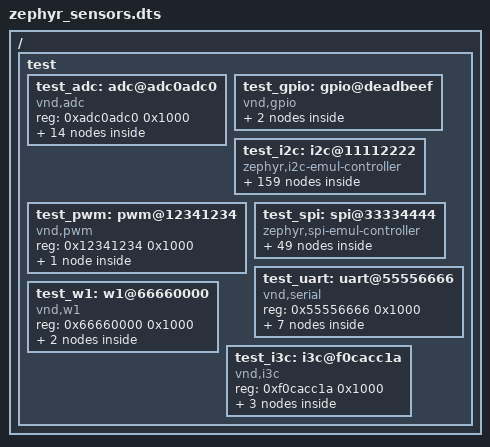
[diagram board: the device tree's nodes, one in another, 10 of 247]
/dts-v1/;

/ {
	test {
		#address-cells = < 0x1 >;
		#size-cells = < 0x1 >;
		test_adc: adc@adc0adc0 {
			compatible = "vnd,adc";
			reg = < 0xadc0adc0 0x1000 >;
			#io-channel-cells = < 0x1 >;
			#address-cells = < 0x1 >;
			#size-cells = < 0x0 >;
			status = "okay";
			phandle = < 0x1 >;
			channel@0 {
				reg = < 0x0 >;
				zephyr,gain = "ADC_GAIN_1";
				zephyr,reference = "ADC_REF_VDD_1";
				zephyr,acquisition-time = < 0x0 >;
				zephyr,input-positive = < 0x0 >;
				zephyr,resolution = < 0xc >;
			};
			channel@1 {
				reg = < 0x1 >;
				zephyr,gain = "ADC_GAIN_1_6";
				zephyr,reference = "ADC_REF_INTERNAL";
				zephyr,acquisition-time = < 0x0 >;
				zephyr,input-positive = < 0x0 >;
				zephyr,resolution = < 0xc >;
			};
			channel@2 {
				reg = < 0x2 >;
				zephyr,gain = "ADC_GAIN_1_6";
				zephyr,reference = "ADC_REF_INTERNAL";
				zephyr,acquisition-time = < 0x0 >;
				zephyr,input-positive = < 0x0 >;
				zephyr,resolution = < 0xc >;
			};
			test_adc_mcp9700a: mcp9700a {
				status = "okay";
				compatible = "microchip,mcp970x";
				family = "MCP9700/9700A";
				io-channels = < &test_adc 0x0 >;
			};
			test_voltage: voltage {
				status = "okay";
				compatible = "voltage-divider";
				io-channels = < &test_adc 0x1 >;
				io-channel-names = "VOLTAGE";
				output-ohms = < 0xb798 >;
				full-ohms = < 0x23e38 >;
				power-gpios = < &test_gpio 0x0 0x0 >;
				phandle = < 0x3 >;
			};
			test_current: current_amp {
				status = "okay";
				compatible = "current-sense-amplifier";
				io-channels = < &test_adc 0x2 >;
				io-channel-names = "CURRENT_AMP";
				sense-resistor-micro-ohms = < 0xa >;
				sense-gain-mult = < 0x1 >;
				sense-gain-div = < 0x1 >;
				phandle = < 0x4 >;
			};
			test_composite_fuel_gauge: composite_fuel_gauge {
				compatible = "zephyr,fuel-gauge-composite";
				status = "okay";
				battery-voltage = < &test_voltage >;
				battery-current = < &test_current >;
				device-chemistry = "lithium-ion-polymer";
				ocv-capacity-table-0 = < 0x262d70 0x300110 0x3373e0 0x34a0a8 0x35e4e0 0x36f650 0x382700 0x396f20 0x3a9fd0 0x3c0f00 0x3d8600 >;
				charge-full-design-microamp-hours = < 0xf4240 >;
			};
			test_adc_emul: adc-emul {
				compatible = "zephyr,adc-emul";
				nchannels = < 0x2 >;
				ref-internal-mv = < 0xce4 >;
				ref-external1-mv = < 0x1388 >;
				#io-channel-cells = < 0x1 >;
				status = "okay";
			};
			test_adc_ntc_thermistor_generic: ntc-thermistor-generic {
				compatible = "ntc-thermistor-generic";
				io-channels = < &test_adc 0x0 >;
				pullup-uv = < 0x325aa0 >;
				pullup-ohm = < 0x0 >;
				pulldown-ohm = < 0x2710 >;
				connected-positive;
				zephyr,compensation-table = < 0x0 0x0 >, < 0x1 0x1 >;
			};
			test_adc_epcos_b57861s0103a039: epcos-b57861s0103a039 {
				compatible = "epcos,b57861s0103a039";
				io-channels = < &test_adc 0x0 >;
				pullup-uv = < 0x325aa0 >;
				pullup-ohm = < 0x0 >;
				pulldown-ohm = < 0x2710 >;
				connected-positive;
			};
			test_murata_ncp15wb473: murata-ncp15wb473 {
				compatible = "murata,ncp15wb473";
				io-channels = < &test_adc 0x0 >;
				pullup-uv = < 0x325aa0 >;
				pullup-ohm = < 0x0 >;
				pulldown-ohm = < 0x2710 >;
				connected-positive;
			};
			test_tdk_ntcg163jf103ft1: tdk-ntcg163jf103ft1 {
				compatible = "tdk,ntcg163jf103ft1";
				io-channels = < &test_adc 0x0 >;
				pullup-uv = < 0x325aa0 >;
				pullup-ohm = < 0x0 >;
				pulldown-ohm = < 0x2710 >;
				connected-positive;
			};
			test_lm35: lm35 {
				compatible = "lm35";
				io-channels = < &test_adc 0x0 >;
				status = "okay";
			};
			test_murata_ncp15xh103: murata-ncp15xh103 {
				compatible = "murata,ncp15xh103";
				io-channels = < &test_adc 0x0 >;
				pullup-uv = < 0x325aa0 >;
				pullup-ohm = < 0x0 >;
				pulldown-ohm = < 0x2710 >;
				connected-positive;
			};
		};
		test_gpio: gpio@deadbeef {
			compatible = "vnd,gpio";
			gpio-controller;
			reg = < 0xdeadbeef 0x1000 >;
			#gpio-cells = < 0x2 >;
			status = "okay";
			phandle = < 0x2 >;
			test_gpio_sm351lt: sm351lt0 {
				compatible = "honeywell,sm351lt";
				gpios = < &test_gpio 0x0 0x0 >;
			};
			test_gpio_dht22: dht22 {
				compatible = "aosong,dht";
				status = "okay";
				dio-gpios = < &test_gpio 0x0 0x0 >;
			};
		};
		test_i2c: i2c@11112222 {
			#address-cells = < 0x1 >;
			#size-cells = < 0x0 >;
			compatible = "zephyr,i2c-emul-controller";
			reg = < 0x11112222 0x1000 >;
			status = "okay";
			clock-frequency = < 0x186a0 >;
			test_i2c_adt7420: adt7420@0 {
				compatible = "adi,adt7420";
				reg = < 0x0 >;
				int-gpios = < &test_gpio 0x0 0x0 >;
			};
			test_i2c_adxl345: adxl345@1 {
				compatible = "adi,adxl345";
				reg = < 0x1 >;
			};
			test_i2c_adxl372: adxl372@2 {
				compatible = "adi,adxl372";
				reg = < 0x2 >;
				int1-gpios = < &test_gpio 0x0 0x0 >;
			};
			test_i2c_ccs811: ccs811@3 {
				compatible = "ams,ccs811";
				reg = < 0x3 >;
				wake-gpios = < &test_gpio 0x0 0x0 >;
				reset-gpios = < &test_gpio 0x0 0x0 >;
				irq-gpios = < &test_gpio 0x0 0x0 >;
			};
			test_i2c_ens210: ens210@4 {
				compatible = "ams,ens210";
				reg = < 0x4 >;
			};
			test_i2c_iaqcore: iaqcore@5 {
				compatible = "ams,iaqcore";
				reg = < 0x5 >;
			};
			test_i2c_bme280: bme280@6 {
				compatible = "bosch,bme280";
				reg = < 0x6 >;
			};
			test_i2c_apds9960: apds9960@7 {
				compatible = "avago,apds9960";
				reg = < 0x7 >;
				int-gpios = < &test_gpio 0x0 0x0 >;
			};
			test_i2c_bma280: bma280@8 {
				compatible = "bosch,bma280";
				reg = < 0x8 >;
				int1-gpios = < &test_gpio 0x0 0x0 >;
			};
			test_i2c_bmc150_magn: bmc150_magn@9 {
				compatible = "bosch,bmc150_magn";
				reg = < 0x9 >;
				drdy-gpios = < &test_gpio 0x0 0x0 >;
			};
			test_i2c_ak8975: ak8975@a {
				compatible = "asahi-kasei,ak8975";
				reg = < 0xa >;
			};
			test_i2c_bme680: bme680@b {
				compatible = "bosch,bme680";
				reg = < 0xb >;
			};
			test_i2c_bmg160: bmg160@c {
				compatible = "bosch,bmg160";
				reg = < 0xc >;
				int-gpios = < &test_gpio 0x0 0x0 >;
			};
			test_i2c_bmm150: bmm150@d {
				compatible = "bosch,bmm150";
				reg = < 0xd >;
				drdy-gpios = < &test_gpio 0x0 0x0 >;
			};
			test_i2c_hmc5883l: hmc5883l@e {
				compatible = "honeywell,hmc5883l";
				reg = < 0xe >;
				int-gpios = < &test_gpio 0x0 0x0 >;
			};
			test_i2c_hp206c: hp206c@f {
				compatible = "hoperf,hp206c";
				reg = < 0xf >;
			};
			test_i2c_th02: th02@10 {
				compatible = "hoperf,th02";
				reg = < 0x10 >;
			};
			test_i2c_mpu6050: mpu6050@11 {
				compatible = "invensense,mpu6050";
				reg = < 0x11 >;
				int-gpios = < &test_gpio 0x0 0x0 >;
			};
			test_i2c_mpu9250: mpu9250@12 {
				compatible = "invensense,mpu9250";
				reg = < 0x12 >;
				irq-gpios = < &test_gpio 0x0 0x0 >;
				gyro-sr-div = < 0xa >;
				gyro-dlpf = < 0x5 >;
				gyro-fs = < 0xfa >;
				accel-fs = < 0x2 >;
				accel-dlpf = "5.05";
			};
			test_i2c_ina219: ina219@13 {
				compatible = "ti,ina219";
				reg = < 0x13 >;
				brng = < 0x0 >;
				pg = < 0x0 >;
				sadc = < 0xd >;
				badc = < 0xd >;
				shunt-milliohm = < 0x64 >;
				lsb-microamp = < 0xa >;
			};
			test_i2c_isl29035: isl29035@14 {
				compatible = "isil,isl29035";
				reg = < 0x14 >;
				int-gpios = < &test_gpio 0x0 0x0 >;
			};
			test_i2c_max30101: max30101@15 {
				compatible = "maxim,max30101";
				reg = < 0x15 >;
			};
			test_i2c_max44009: max44009@16 {
				compatible = "maxim,max44009";
				reg = < 0x16 >;
				int-gpios = < &test_gpio 0x0 0x0 >;
			};
			test_i2c_ms5607: ms5607@17 {
				compatible = "meas,ms5607";
				reg = < 0x17 >;
			};
			test_i2c_ms5837: ms5837@18 {
				compatible = "meas,ms5837";
				reg = < 0x18 >;
			};
			test_i2c_jc42: jc42@19 {
				compatible = "jedec,jc-42.4-temp";
				reg = < 0x19 >;
				int-gpios = < &test_gpio 0x0 0x0 >;
			};
			test_i2c_fxas21002: fxas21002@1a {
				compatible = "nxp,fxas21002";
				reg = < 0x1a >;
				int1-gpios = < &test_gpio 0x0 0x0 >;
				int2-gpios = < &test_gpio 0x0 0x0 >;
			};
			test_i2c_fxos8700: fxos8700@1b {
				compatible = "nxp,fxos8700";
				reg = < 0x1b >;
				reset-gpios = < &test_gpio 0x0 0x0 >;
				int1-gpios = < &test_gpio 0x0 0x0 >;
				int2-gpios = < &test_gpio 0x0 0x0 >;
			};
			test_i2c_amg88xx: amg88xx@1c {
				compatible = "panasonic,amg88xx";
				reg = < 0x1c >;
				int-gpios = < &test_gpio 0x0 0x0 >;
			};
			test_i2c_sx9500: sx9500@1d {
				compatible = "semtech,sx9500";
				reg = < 0x1d >;
				int-gpios = < &test_gpio 0x0 0x0 >;
			};
			test_i2c_sgp40: sgp40@1e {
				compatible = "sensirion,sgp40";
				reg = < 0x1e >;
				enable-selftest;
			};
			test_i2c_sht3xd: sht3xd@1f {
				compatible = "sensirion,sht3xd";
				reg = < 0x1f >;
				alert-gpios = < &test_gpio 0x0 0x0 >;
			};
			test_i2c_sht4xd: sht4x@20 {
				compatible = "sensirion,sht4x";
				reg = < 0x20 >;
				repeatability = < 0x2 >;
			};
			test_i2c_shtc3: shtc3@21 {
				compatible = "sensirion,shtc3", "sensirion,shtcx";
				reg = < 0x21 >;
				measure-mode = "normal";
				clock-stretching;
			};
			test_i2c_si7006: si7006@22 {
				compatible = "silabs,si7006";
				reg = < 0x22 >;
			};
			test_i2c_si7055: si7055@23 {
				compatible = "silabs,si7055";
				reg = < 0x23 >;
			};
			test_i2c_si7060: si7060@24 {
				compatible = "silabs,si7060";
				reg = < 0x24 >;
			};
			test_i2c_si7210: si7010@25 {
				compatible = "silabs,si7210";
				reg = < 0x25 >;
			};
			test_i2c_hts221: hts221@26 {
				compatible = "st,hts221";
				reg = < 0x26 >;
				drdy-gpios = < &test_gpio 0x0 0x0 >;
			};
			test_i2c_iis2dlpc: iis2dlpc@27 {
				compatible = "st,iis2dlpc";
				reg = < 0x27 >;
				drdy-gpios = < &test_gpio 0x0 0x0 >;
				tap-mode = < 0x1 >;
				power-mode = < 0x4 >;
			};
			test_i2c_iis2mdc: iis2mdc@28 {
				compatible = "st,iis2mdc";
				reg = < 0x28 >;
				drdy-gpios = < &test_gpio 0x0 0x0 >;
			};
			test_i2c_ism330dhcx: ism330dhcx@29 {
				compatible = "st,ism330dhcx";
				reg = < 0x29 >;
				drdy-gpios = < &test_gpio 0x0 0x0 >;
				accel-odr = < 0x4 >;
				gyro-odr = < 0x4 >;
				status = "disabled";
			};
			test_i2c_lis2dh: lis2dh@2a {
				compatible = "st,lis2dh";
				reg = < 0x2a >;
				irq-gpios = < &test_gpio 0x0 0x0 >;
				int1-gpio-config = < 0x4 >;
				int2-gpio-config = < 0x4 >;
				anym-mode = < 0x3 >;
			};
			test_i2c_lis2dh12: lis2dh12@2b {
				compatible = "st,lis2dh12";
				reg = < 0x2b >;
				irq-gpios = < &test_gpio 0x0 0x0 >;
				status = "disabled";
			};
			test_i2c_lis2ds12: lis2ds12@2c {
				compatible = "st,lis2ds12";
				reg = < 0x2c >;
				irq-gpios = < &test_gpio 0x0 0x0 >;
				power-mode = < 0x1 >;
				odr = < 0x2 >;
			};
			test_i2c_lis2dw12: lis2dw12@2d {
				compatible = "st,lis2dw12";
				reg = < 0x2d >;
				irq-gpios = < &test_gpio 0x0 0x0 >;
				wakeup-duration = < 0x3 >;
				ff-threshold = < 0x7 >;
				tap-mode = < 0x1 >;
				power-mode = < 0x4 >;
				bw-filt = < 0x0 >;
			};
			test_i2c_lis2mdl: lis2mdl@2e {
				compatible = "st,lis2mdl";
				reg = < 0x2e >;
				irq-gpios = < &test_gpio 0x0 0x0 >;
			};
			test_i2c_lis3dh: lis3dh@2f {
				compatible = "st,lis3dh";
				reg = < 0x2f >;
				irq-gpios = < &test_gpio 0x0 0x0 >;
				status = "disabled";
			};
			test_i2c_lis3mdl_magn: lis3mdl-magn@30 {
				compatible = "st,lis3mdl-magn";
				reg = < 0x30 >;
				irq-gpios = < &test_gpio 0x0 0x0 >;
			};
			test_i2c_lps22hb_press: lps22hb-press@31 {
				compatible = "st,lps22hb-press";
				reg = < 0x31 >;
			};
			test_i2c_lps22hh: lps22hh@32 {
				compatible = "st,lps22hh";
				reg = < 0x32 >;
				drdy-gpios = < &test_gpio 0x0 0x0 >;
				odr = < 0x7 >;
			};
			test_i2c_lps25hb_press: lps25hb-press@33 {
				compatible = "st,lps25hb-press";
				reg = < 0x33 >;
			};
			test_i2c_lsm303agr_accel: lsm303agr-accel@34 {
				compatible = "st,lsm303agr-accel";
				reg = < 0x34 >;
				irq-gpios = < &test_gpio 0x0 0x0 >;
				status = "disabled";
			};
			test_i2c_lsm303dlhc_accel: lsm303dlhc-accel@35 {
				compatible = "st,lsm303dlhc-accel";
				reg = < 0x35 >;
				irq-gpios = < &test_gpio 0x0 0x0 >;
				status = "disabled";
			};
			test_i2c_lsm303dlhc_magn: lsm303dlhc-magn@36 {
				compatible = "st,lsm303dlhc-magn";
				reg = < 0x36 >;
			};
			test_i2c_lsm6ds0: lsm6ds0@37 {
				compatible = "st,lsm6ds0";
				reg = < 0x37 >;
			};
			test_i2c_lsm6dsl: lsm6dsl@38 {
				compatible = "st,lsm6dsl";
				reg = < 0x38 >;
				irq-gpios = < &test_gpio 0x0 0x0 >;
			};
			test_i2c_lsm6dso: lsm6dso@39 {
				compatible = "st,lsm6dso";
				reg = < 0x39 >;
				irq-gpios = < &test_gpio 0x0 0x0 >;
				accel-pm = < 0x2 >;
				accel-range = < 0x3 >;
				accel-odr = < 0xb >;
				gyro-pm = < 0x1 >;
				gyro-range = < 0x6 >;
				gyro-odr = < 0xa >;
			};
			test_i2c_lsm9ds0_gyro: lsm9ds0-gyro@3a {
				compatible = "st,lsm9ds0-gyro";
				reg = < 0x3a >;
				irq-gpios = < &test_gpio 0x0 0x0 >;
			};
			test_i2c_lsm9ds0_mfd: lsm9ds0-mfd@3b {
				compatible = "st,lsm9ds0-mfd";
				reg = < 0x3b >;
				irq-gpios = < &test_gpio 0x0 0x0 >;
			};
			test_i2c_stts751: stts751@3c {
				compatible = "st,stts751";
				reg = < 0x3c >;
				drdy-gpios = < &test_gpio 0x0 0x0 >;
			};
			test_i2c_vl53l0x: vl53l0x@3d {
				compatible = "st,vl53l0x";
				reg = < 0x3d >;
				xshut-gpios = < &test_gpio 0x0 0x0 >;
			};
			test_i2c_hdc: hdc@3e {
				compatible = "ti,hdc";
				reg = < 0x3e >;
				drdy-gpios = < &test_gpio 0x0 0x0 >;
			};
			test_i2c_hdc2010: hdc2010@3f {
				compatible = "ti,hdc2010";
				reg = < 0x3f >;
			};
			test_i2c_hdc2021: hdc2021@40 {
				compatible = "ti,hdc2021";
				reg = < 0x40 >;
			};
			test_i2c_hdc2022: hdc2022@41 {
				compatible = "ti,hdc2022";
				reg = < 0x41 >;
			};
			test_i2c_hdc2080: hdc2080@42 {
				compatible = "ti,hdc2080";
				reg = < 0x42 >;
			};
			test_i2c_opt3001: opt3001@43 {
				compatible = "ti,opt3001";
				reg = < 0x43 >;
			};
			test_i2c_tmp007: tmp007@44 {
				compatible = "ti,tmp007";
				reg = < 0x44 >;
				int-gpios = < &test_gpio 0x0 0x0 >;
			};
			test_i2c_tmp108: tmp108@45 {
				compatible = "ti,tmp108";
				reg = < 0x45 >;
				alert-gpios = < &test_gpio 0x0 0x0 >;
			};
			test_i2c_tmp112: tmp112@46 {
				compatible = "ti,tmp112";
				reg = < 0x46 >;
			};
			test_i2c_tmp116: tmp116@47 {
				compatible = "ti,tmp116";
				reg = < 0x47 >;
			};
			test_i2c_bq274xx: bq27xx@48 {
				compatible = "ti,bq274xx";
				reg = < 0x48 >;
				design-voltage = < 0xe74 >;
				design-capacity = < 0x708 >;
				taper-current = < 0x2d >;
				terminate-voltage = < 0xbb8 >;
				int-gpios = < &test_gpio 0x0 0x0 >;
			};
			test_i2c_mpr: mpr@49 {
				compatible = "honeywell,mpr";
				reg = < 0x49 >;
			};
			test_i2c_dps310: dps310@4a {
				compatible = "infineon,dps310";
				reg = < 0x4a >;
			};
			test_i2c_iis2dh: iis2dh@4b {
				compatible = "st,iis2dh";
				reg = < 0x4b >;
				drdy-gpios = < &test_gpio 0x0 0x0 >;
			};
			test_i2c_iis2iclx: iis2iclx@4c {
				compatible = "st,iis2iclx";
				reg = < 0x4c >;
				drdy-gpios = < &test_gpio 0x0 0x0 >;
				int-pin = < 0x1 >;
				range = < 0x3 >;
				odr = < 0x7 >;
			};
			test_i2c_wsen_hids: wsen_hids@4d {
				compatible = "we,wsen-hids";
				reg = < 0x4d >;
				drdy-gpios = < &test_gpio 0x0 0x0 >;
				odr = "1";
			};
			test_i2c_itds: itds@4e {
				compatible = "we,wsen-itds";
				reg = < 0x4e >;
				int-gpios = < &test_gpio 0x0 0x0 >;
				odr = "800";
				op-mode = "high-perf";
			};
			test_i2c_max17055: max17055@4f {
				compatible = "maxim,max17055";
				reg = < 0x4f >;
				design-capacity = < 0x5dc >;
				design-voltage = < 0xf14 >;
				desired-charging-current = < 0x7d0 >;
				desired-voltage = < 0x1130 >;
				i-chg-term = < 0x64 >;
				rsense-mohms = < 0x5 >;
				v-empty = < 0xce4 >;
			};
			test_i2c_max17262: max17262@50 {
				compatible = "maxim,max17262";
				reg = < 0x50 >;
				design-voltage = < 0xe10 >;
				desired-voltage = < 0xe10 >;
				desired-charging-current = < 0x7d0 >;
				design-cap = < 0x4268 >;
				empty-voltage = < 0xce4 >;
				recovery-voltage = < 0xf28 >;
				charge-voltage = < 0xe10 >;
			};
			test_i2c_vcnl4040: vcnl4040@51 {
				compatible = "vishay,vcnl4040";
				reg = < 0x51 >;
				int-gpios = < &test_gpio 0x0 0x0 >;
			};
			test_i2c_bmi160: bmi160@52 {
				compatible = "bosch,bmi160";
				reg = < 0x52 >;
				int-gpios = < &test_gpio 0x0 0x0 >;
			};
			test_i2c_bmi270: bmi270@53 {
				compatible = "bosch,bmi270";
				reg = < 0x53 >;
				irq-gpios = < &test_gpio 0x0 0x0 >;
			};
			test_i2c_fdc2x1x: fdc2x1x@54 {
				compatible = "ti,fdc2x1x";
				reg = < 0x54 >;
				intb-gpios = < &test_gpio 0x0 0x0 >;
				sd-gpios = < &test_gpio 0x0 0x0 >;
				deglitch = < 0x5 >;
				fref = < 0xa960 >;
				channel_0 {
					rcount = < 0x1d4b >;
					settlecount = < 0x30 >;
					fref-divider = < 0x1 >;
					idrive = < 0xa >;
					fin-sel = < 0x2 >;
					inductance = < 0x12 >;
				};
			};
			test_i2c_bmp388: bmp388@55 {
				compatible = "bosch,bmp388";
				reg = < 0x55 >;
				int-gpios = < &test_gpio 0x0 0x0 >;
			};
			test_i2c_lm75: lm75@56 {
				compatible = "lm75";
				reg = < 0x56 >;
				int-gpios = < &test_gpio 0x0 0x0 >;
			};
			test_i2c_ina230: ina230@57 {
				compatible = "ti,ina230";
				reg = < 0x57 >;
				current-lsb-microamps = < 0x3e8 >;
				rshunt-micro-ohms = < 0x3e8 >;
				mask = < 0x0 >;
				alert-limit = < 0x0 >;
				alert-gpios = < &test_gpio 0x0 0x0 >;
			};
			test_i2c_lm77: lm77@58 {
				compatible = "lm77";
				reg = < 0x58 >;
				int-gpios = < &test_gpio 0x0 0x0 >;
			};
			test_i2c_ina231: ina231@59 {
				compatible = "ti,ina230";
				reg = < 0x59 >;
				current-lsb-microamps = < 0x3e8 >;
				rshunt-micro-ohms = < 0x3e8 >;
				mask = < 0x0 >;
				alert-limit = < 0x0 >;
				alert-gpios = < &test_gpio 0x0 0x0 >;
			};
			test_i2c_ina237: ina237@5a {
				compatible = "ti,ina237";
				reg = < 0x5a >;
				current-lsb-microamps = < 0x3e8 >;
				rshunt-micro-ohms = < 0x3e8 >;
				alert-config = < 0x0 >;
				alert-gpios = < &test_gpio 0x0 0x0 >;
			};
			test_i2c_max31875: max31875@5b {
				compatible = "maxim,max31875";
				reg = < 0x5b >;
			};
			test_i2c_icp10125: icp10125@5c {
				compatible = "invensense,icp10125";
				reg = < 0x5c >;
				temperature-measurement-mode = "normal";
				pressure-measurement-mode = "normal";
			};
			test_i2c_as5600: as5600@5d {
				compatible = "ams,as5600";
				reg = < 0x5d >;
			};
			test_i2c_bh1750: bh1750@5e {
				compatible = "rohm,bh1750";
				reg = < 0x5e >;
			};
			test_i2c_akm09918c: akm09918c@5f {
				compatible = "asahi-kasei,akm09918c";
				reg = < 0x5f >;
			};
			test_i2c_wsen_tids: wsen_tids@60 {
				compatible = "we,wsen-tids";
				reg = < 0x60 >;
				int-gpios = < &test_gpio 0x0 0x0 >;
				odr = < 0x19 >;
				temp-high-threshold = < 0x0 >;
				temp-low-threshold = < 0x0 >;
			};
			test_i2c_vl53l1x: vl53l1x@61 {
				compatible = "st,vl53l1x";
				reg = < 0x61 >;
				int-gpios = < &test_gpio 0x0 0x0 >;
				xshut-gpios = < &test_gpio 0x0 0x0 >;
			};
			test_i2c_tmd2620: tmd2620@62 {
				compatible = "ams,tmd2620";
				reg = < 0x62 >;
				int-gpios = < &test_gpio 0x0 0x0 >;
				proximity-gain = < 0x4 >;
				proximity-pulse-length = < 0x10 >;
				proximity-pulse-count = < 0xf >;
				proximity-high-threshold = < 0xff >;
				proximity-low-threshold = < 0x0 >;
				proximity-led-drive-strength = < 0x4 >;
				proximity-interrupt-filter = < 0x0 >;
				wait-time-factor = < 0x0 >;
			};
			test_i2c_wsen_pads: wsen_pads@63 {
				compatible = "we,wsen-pads";
				reg = < 0x63 >;
				drdy-gpios = < &test_gpio 0x0 0x0 >;
				odr = < 0x1 >;
			};
			test_i2c_s11059: s11059@64 {
				compatible = "hamamatsu,s11059";
				reg = < 0x64 >;
				integration-time = < 0x854d0 >;
			};
			test_i2c_wsen_pdus: wsen_pdus@65 {
				compatible = "we,wsen-pdus";
				reg = < 0x65 >;
				sensor-type = < 0x3 >;
			};
			test_i2c_veml7700: veml7700@66 {
				compatible = "vishay,veml7700";
				reg = < 0x66 >;
				psm-mode = < 0x3 >;
			};
			test_i2c_ina3221: ina3221@67 {
				compatible = "ti,ina3221";
				reg = < 0x67 >;
				shunt-resistors = < 0x3e8 0x3e8 0x3e8 >;
				enable-channel = < 0x1 0x0 0x0 >;
				conv-time-bus = < 0x7 >;
				conv-time-shunt = < 0x7 >;
				avg-mode = < 0x2 >;
			};
			test_i2c_lsm6dso16is: lsm6dso16is@68 {
				compatible = "st,lsm6dso16is";
				reg = < 0x68 >;
				irq-gpios = < &test_gpio 0x0 0x0 >;
				accel-range = < 0x3 >;
				accel-odr = < 0x14 >;
				gyro-range = < 0x3 >;
				gyro-odr = < 0x14 >;
			};
			test_i2c_lsm6dsv16x: lsm6dsv16x@69 {
				compatible = "st,lsm6dsv16x";
				reg = < 0x69 >;
				int1-gpios = < &test_gpio 0x0 0x0 >;
				int2-gpios = < &test_gpio 0x0 0x0 >;
				accel-range = < 0x2 >;
				accel-odr = < 0x5 >;
				gyro-range = < 0x4 >;
				gyro-odr = < 0x5 >;
			};
			test_i2c_mcp9600: mcp9600@6a {
				compatible = "microchip,mcp9600";
				reg = < 0x6a >;
			};
			test_i2c_tcs3400: tcs3400@6b {
				compatible = "ams,tcs3400";
				reg = < 0x6b >;
				int-gpios = < &test_gpio 0x0 0x0 >;
			};
			test_i2c_tcn75a: tcn75a@6c {
				compatible = "microchip,tcn75a";
				reg = < 0x6c >;
				alert-gpios = < &test_gpio 0x0 0x0 >;
			};
			test_i2c_bmi08x_accel: bmi08x@6d {
				compatible = "bosch,bmi08x-accel";
				reg = < 0x6d >;
				int-gpios = < &test_gpio 0x0 0x0 >;
				int1-map-io = < 0x1 >;
				int2-map-io = < 0x0 >;
				int1-conf-io = < 0xa >;
				int2-conf-io = < 0x17 >;
				accel-hz = "800";
				accel-fs = < 0x4 >;
			};
			test_i2c_bmi08x_gyro: bmi08x@6e {
				compatible = "bosch,bmi08x-gyro";
				reg = < 0x6e >;
				int-gpios = < &test_gpio 0x0 0x0 >;
				int3-4-map-io = < 0x1 >;
				int3-4-conf-io = < 0x1 >;
				gyro-hz = "1000_116";
				gyro-fs = < 0x3e8 >;
			};
			test_i2c_ist8310: ist8310@6f {
				compatible = "isentek,ist8310";
				reg = < 0x6f >;
				status = "okay";
			};
			test_i2c_f75303: f75303@70 {
				compatible = "fintek,f75303";
				reg = < 0x70 >;
			};
			test_i2c_tsl2540: tsl2540@71 {
				compatible = "ams,tsl2540";
				reg = < 0x71 >;
				int-gpios = < &test_gpio 0x0 0x0 >;
			};
			test_i2c_adltc2990@72 {
				compatible = "adi,adltc2990";
				reg = < 0x72 >;
				status = "okay";
				measurement-mode = < 0x7 0x3 >;
				pins-v1-v2-current-resistor = < 0x1 >;
				pin-v1-voltage-divider-resistors = < 0x64 0xa >;
				pin-v2-voltage-divider-resistors = < 0x64 0xa >;
				pin-v3-voltage-divider-resistors = < 0x64 0x64 >;
				pin-v4-voltage-divider-resistors = < 0x0 0x1 >;
			};
			test_i2c_hm330x@73 {
				compatible = "seeed,hm330x";
				reg = < 0x73 >;
				status = "okay";
			};
			test_i2c_amd_sb_tsi: amd_sb_tsi@74 {
				compatible = "amd,sb-tsi";
				reg = < 0x74 >;
			};
			test_i2c_mc3419: mc3419@75 {
				compatible = "memsic,mc3419";
				reg = < 0x75 >;
				int-gpios = < &test_gpio 0x0 0x0 >;
			};
			test_i2c_ltrf216a0: ltrf216a@76 {
				compatible = "ltr,f216a";
				reg = < 0x76 >;
			};
			test_i2c_adxl367: adxl367@77 {
				compatible = "adi,adxl367";
				reg = < 0x77 >;
				odr = < 0x4 >;
				int1-gpios = < &test_gpio 0x0 0x0 >;
			};
			test_i2c_tsl2561: tsl2561@78 {
				compatible = "ams,tsl2561";
				reg = < 0x78 >;
			};
			test_i2c_lps22df: lps22df@79 {
				compatible = "st,lps22df";
				reg = < 0x79 >;
				drdy-gpios = < &test_gpio 0x0 0x0 >;
				status = "okay";
				odr = < 0x3 >;
				lpf = < 0x1 >;
				avg = < 0x5 >;
			};
			test_i2c_hs300x: hs300x@7a {
				compatible = "renesas,hs300x";
				reg = < 0x7a >;
			};
			test_i2c_lps28dfw: lps28dfw@7b {
				compatible = "st,lps28dfw";
				reg = < 0x7b >;
				drdy-gpios = < &test_gpio 0x0 0x0 >;
				status = "okay";
				odr = < 0x3 >;
				lpf = < 0x1 >;
				avg = < 0x5 >;
				fs = < 0x0 >;
			};
			test_i2c_lis2du12: lis2du12@7c {
				compatible = "st,lis2du12";
				reg = < 0x7c >;
				int1-gpios = < &test_gpio 0x0 0x0 >;
				int2-gpios = < &test_gpio 0x0 0x0 >;
				accel-range = < 0x3 >;
				accel-odr = < 0xb >;
			};
			test_i2c_bma4xx: bma4xx@7d {
				compatible = "bosch,bma4xx";
				reg = < 0x7d >;
			};
			test_i2c_ags10: ags10@7e {
				compatible = "aosong,ags10";
				reg = < 0x7e >;
			};
			test_i2c_bmp581: bmp581@7f {
				compatible = "bosch,bmp581";
				reg = < 0x7f >;
				int-gpios = < &test_gpio 0x0 0x0 >;
			};
			test_i2c_lis2de12: lis2de12@80 {
				compatible = "st,lis2de12";
				reg = < 0x80 >;
				int1-gpios = < &test_gpio 0x0 0x0 >;
				int2-gpios = < &test_gpio 0x0 0x0 >;
				accel-range = < 0x3 >;
				accel-odr = < 0x5 >;
			};
			test_i2c_vishay_vcnl36825t: vcnl36825t@81 {
				compatible = "vishay,vcnl36825t";
				reg = < 0x81 >;
				proximity-it = "1";
				multi-pulse = < 0x8 >;
				low-power;
			};
			test_i2c_tmag5273: tmag5273@82 {
				compatible = "ti,tmag5273";
				status = "okay";
				reg = < 0x82 >;
				int-gpios = < &test_gpio 0xf 0x1 >;
				operation-mode = < 0x0 >;
				angle-magnitude-axis = < 0x1 >;
			};
			test_i2c_ens160: ens160@83 {
				compatible = "sciosense,ens160";
				reg = < 0x83 >;
				int-gpios = < &test_gpio 0x0 0x0 >;
			};
			test_i2c_tsl2591: tsl2591@84 {
				compatible = "ams,tsl2591";
				reg = < 0x84 >;
				int-gpios = < &test_gpio 0x0 0x0 >;
			};
			test_i2c_max31790: max31790@85 {
				compatible = "maxim,max31790";
				status = "okay";
				reg = < 0x85 >;
				max31790_fan_fault: max31790_fan_fault {
					compatible = "maxim,max31790-fan-fault";
					status = "okay";
				};
				max31790_fan_speed_1: max31790_fan_speed_1 {
					compatible = "maxim,max31790-fan-speed";
					status = "okay";
					channel = < 0x1 >;
				};
				max31790_fan_speed_2: max31790_fan_speed_2 {
					compatible = "maxim,max31790-fan-speed";
					status = "okay";
					channel = < 0x2 >;
				};
				max31790_fan_speed_3: max31790_fan_speed_3 {
					compatible = "maxim,max31790-fan-speed";
					status = "okay";
					channel = < 0x3 >;
				};
				max31790_fan_speed_4: max31790_fan_speed_4 {
					compatible = "maxim,max31790-fan-speed";
					status = "okay";
					channel = < 0x4 >;
				};
				max31790_fan_speed_5: max31790_fan_speed_5 {
					compatible = "maxim,max31790-fan-speed";
					status = "okay";
					channel = < 0x5 >;
				};
				max31790_fan_speed_6: max31790_fan_speed_6 {
					compatible = "maxim,max31790-fan-speed";
					status = "okay";
					channel = < 0x6 >;
				};
			};
			test_i2c_stts22h: stts22h@86 {
				compatible = "st,stts22h";
				reg = < 0x86 >;
				int-gpios = < &test_gpio 0x0 0x0 >;
				sampling-rate = < 0x22 >;
			};
			test_i2c_dht20: dht20@87 {
				compatible = "aosong,dht20";
				reg = < 0x87 >;
				status = "okay";
			};
			test_i2c_aht20: aht20@88 {
				compatible = "aosong,aht20";
				reg = < 0x88 >;
				status = "okay";
			};
			test_i2c_am2301b: am2301b@89 {
				compatible = "aosong,am2301b";
				reg = < 0x89 >;
			};
			test_i2c_lis2dux12: lis2dux12@8a {
				compatible = "st,lis2dux12";
				reg = < 0x8a >;
				int1-gpios = < &test_gpio 0x0 0x0 >;
				int2-gpios = < &test_gpio 0x0 0x0 >;
				range = < 0x3 >;
				odr = < 0x8 >;
				power-mode = < 0x3 >;
				status = "okay";
			};
			test_i2c_iis328dq: iis328dq@8b {
				compatible = "st,iis328dq";
				status = "okay";
				reg = < 0x8b >;
				int2-gpios = < &test_gpio 0x0 0x0 >;
				threshold-int-pad = < 0x2 >;
			};
			test_i2c_nct75: test_i2c_nct75@8c {
				compatible = "onnn,nct75";
				reg = < 0x8c >;
				status = "okay";
			};
			test_i2c_tmp114: tmp114@8d {
				compatible = "ti,tmp114";
				reg = < 0x8d >;
			};
			test_i2c_ina226: ina226@8e {
				compatible = "ti,ina226";
				reg = < 0x8e >;
				current-lsb-microamps = < 0x1388 >;
				rshunt-micro-ohms = < 0x1f4 >;
			};
			test_i2c_shtc1: shtc1@8f {
				compatible = "sensirion,shtc1", "sensirion,shtcx";
				reg = < 0x8f >;
				measure-mode = "low-power";
				clock-stretching;
			};
			test_i2c_lm95234: lm95234@90 {
				compatible = "national,lm95234";
				reg = < 0x90 >;
				status = "okay";
			};
			test_i2c_sht21@91 {
				compatible = "sensirion,sht21";
				reg = < 0x91 >;
			};
			test_i2c_lsm9ds1: lsm9ds1@92 {
				compatible = "st,lsm9ds1";
				reg = < 0x92 >;
			};
			test_i2c_icm42670: icm42670@92 {
				compatible = "invensense,icm42670";
				reg = < 0x92 >;
				int-gpios = < &test_gpio 0x0 0x0 >;
				accel-hz = < 0x320 >;
				accel-fs = < 0x10 >;
				gyro-hz = < 0x320 >;
				gyro-fs = < 0x7d0 >;
			};
			test_i2c_fxls8974: fxls8974@93 {
				compatible = "nxp,fxls8974";
				reg = < 0x93 >;
				reset-gpios = < &test_gpio 0x0 0x0 >;
				int1-gpios = < &test_gpio 0x0 0x0 >;
				int2-gpios = < &test_gpio 0x0 0x0 >;
			};
			test_i2c_bmp180: bmp180@94 {
				compatible = "bosch,bmp180";
				reg = < 0x94 >;
				osr-press = < 0x1 >;
			};
			test_i2c_apds9253: apds9253@91 {
				compatible = "avago,apds9253";
				reg = < 0x91 >;
				int-gpios = < &test_gpio 0x0 0x0 >;
				gain = < 0x0 >;
				rate = < 0x1 >;
				resolution = < 0x40 >;
			};
		};
		test_pwm: pwm@12341234 {
			compatible = "vnd,pwm";
			reg = < 0x12341234 0x1000 >;
			#pwm-cells = < 0x3 >;
			status = "okay";
			phandle = < 0x5 >;
			test_pwm_tsic_xx6: tsic_xx6 {
				status = "okay";
				compatible = "ist,tsic-xx6";
				pwms = < &test_pwm 0x0 0x0 0x0 >;
				data-bits = < 0xe >;
				lower-temperature-limit = < 0xffffff9c >;
				higher-temperature-limit = < 0xfa >;
			};
		};
		test_spi: spi@33334444 {
			#address-cells = < 0x1 >;
			#size-cells = < 0x0 >;
			compatible = "zephyr,spi-emul-controller";
			reg = < 0x33334444 0x1000 >;
			status = "okay";
			clock-frequency = < 0x1e8480 >;
			cs-gpios = < &test_gpio 0x0 0x0 >, < &test_gpio 0x0 0x0 >, < &test_gpio 0x0 0x0 >, < &test_gpio 0x0 0x0 >, < &test_gpio 0x0 0x0 >, < &test_gpio 0x0 0x0 >, < &test_gpio 0x0 0x0 >, < &test_gpio 0x0 0x0 >, < &test_gpio 0x0 0x0 >, < &test_gpio 0x0 0x0 >, < &test_gpio 0x0 0x0 >, < &test_gpio 0x0 0x0 >, < &test_gpio 0x0 0x0 >, < &test_gpio 0x0 0x0 >, < &test_gpio 0x0 0x0 >, < &test_gpio 0x0 0x0 >, < &test_gpio 0x0 0x0 >, < &test_gpio 0x0 0x0 >, < &test_gpio 0x0 0x0 >, < &test_gpio 0x0 0x0 >, < &test_gpio 0x0 0x0 >, < &test_gpio 0x0 0x0 >, < &test_gpio 0x0 0x0 >, < &test_gpio 0x0 0x0 >, < &test_gpio 0x0 0x0 >, < &test_gpio 0x0 0x0 >, < &test_gpio 0x0 0x0 >, < &test_gpio 0x0 0x0 >, < &test_gpio 0x0 0x0 >, < &test_gpio 0x0 0x0 >, < &test_gpio 0x0 0x0 >, < &test_gpio 0x0 0x0 >, < &test_gpio 0x0 0x0 >, < &test_gpio 0x0 0x0 >, < &test_gpio 0x0 0x0 >, < &test_gpio 0x0 0x0 >, < &test_gpio 0x0 0x0 >, < &test_gpio 0x0 0x0 >, < &test_gpio 0x0 0x0 >, < &test_gpio 0x0 0x0 >, < &test_gpio 0x0 0x0 >, < &test_gpio 0x0 0x0 >, < &test_gpio 0x0 0x0 >, < &test_gpio 0x0 0x0 >, < &test_gpio 0x0 0x0 >, < &test_gpio 0x0 0x0 >, < &test_gpio 0x0 0x0 >;
			test_spi_adxl362: adxl362@0 {
				compatible = "adi,adxl362";
				reg = < 0x0 >;
				spi-max-frequency = < 0x0 >;
				int1-gpios = < &test_gpio 0x0 0x0 >;
			};
			test_spi_adxl372: adxl372@1 {
				compatible = "adi,adxl372";
				reg = < 0x1 >;
				spi-max-frequency = < 0x0 >;
				int1-gpios = < &test_gpio 0x0 0x0 >;
			};
			test_spi_bme280: bme280@2 {
				compatible = "bosch,bme280";
				reg = < 0x2 >;
				spi-max-frequency = < 0x0 >;
				status = "disabled";
			};
			test_spi_bmi160: bmi160@3 {
				compatible = "bosch,bmi160";
				reg = < 0x3 >;
				spi-max-frequency = < 0x0 >;
				int-gpios = < &test_gpio 0x0 0x0 >;
			};
			test_spi_ms5607: ms5607@4 {
				compatible = "meas,ms5607";
				reg = < 0x4 >;
				spi-max-frequency = < 0x0 >;
			};
			test_spi_iis2dlpc: iis2dlpc@5 {
				compatible = "st,iis2dlpc";
				reg = < 0x5 >;
				spi-max-frequency = < 0x0 >;
				drdy-gpios = < &test_gpio 0x0 0x0 >;
			};
			test_spi_iis2mdc: iis2mdc@6 {
				compatible = "st,iis2mdc";
				reg = < 0x6 >;
				spi-max-frequency = < 0x0 >;
				drdy-gpios = < &test_gpio 0x0 0x0 >;
			};
			test_spi_iis3dhhc: iis3dhhc@7 {
				compatible = "st,iis3dhhc";
				reg = < 0x7 >;
				spi-max-frequency = < 0x0 >;
				irq-gpios = < &test_gpio 0x0 0x0 >;
			};
			test_spi_ism330dhcx: ism330dhcx@8 {
				compatible = "st,ism330dhcx";
				reg = < 0x8 >;
				spi-max-frequency = < 0x0 >;
				drdy-gpios = < &test_gpio 0x0 0x0 >;
			};
			test_spi_lis2dh: lis2dh@9 {
				compatible = "st,lis2dh";
				reg = < 0x9 >;
				spi-max-frequency = < 0x0 >;
				irq-gpios = < &test_gpio 0x0 0x0 >;
			};
			test_spi_lis2ds12: lis2ds12@a {
				compatible = "st,lis2ds12";
				reg = < 0xa >;
				spi-max-frequency = < 0x0 >;
				irq-gpios = < &test_gpio 0x0 0x0 >;
			};
			test_spi_lis2dw12: lis2dw12@b {
				compatible = "st,lis2dw12";
				reg = < 0xb >;
				spi-max-frequency = < 0x0 >;
				irq-gpios = < &test_gpio 0x0 0x0 >;
			};
			test_spi_lis2mdl: lis2mdl@c {
				compatible = "st,lis2mdl";
				reg = < 0xc >;
				spi-max-frequency = < 0x0 >;
				irq-gpios = < &test_gpio 0x0 0x0 >;
			};
			test_spi_lps22hh: lps22hh@d {
				compatible = "st,lps22hh";
				reg = < 0xd >;
				spi-max-frequency = < 0x0 >;
				drdy-gpios = < &test_gpio 0x0 0x0 >;
			};
			test_spi_lsm303agr_accel: lsm303agr-accel@e {
				compatible = "st,lsm303agr-accel";
				reg = < 0xe >;
				spi-max-frequency = < 0x0 >;
				irq-gpios = < &test_gpio 0x0 0x0 >;
				status = "disabled";
			};
			test_spi_lsm6dsl: lsm6dsl@f {
				compatible = "st,lsm6dsl";
				reg = < 0xf >;
				spi-max-frequency = < 0x0 >;
				irq-gpios = < &test_gpio 0x0 0x0 >;
			};
			test_spi_lsm6dso: lsm6dso@10 {
				compatible = "st,lsm6dso";
				reg = < 0x10 >;
				spi-max-frequency = < 0x0 >;
				irq-gpios = < &test_gpio 0x0 0x0 >;
			};
			test_spi_iis2dh: iis2dh@11 {
				compatible = "st,iis2dh";
				reg = < 0x11 >;
				spi-max-frequency = < 0x0 >;
				drdy-gpios = < &test_gpio 0x0 0x0 >;
				status = "disabled";
			};
			test_spi_iis2iclx: iis2iclx@12 {
				compatible = "st,iis2iclx";
				reg = < 0x12 >;
				spi-max-frequency = < 0x0 >;
				drdy-gpios = < &test_gpio 0x0 0x0 >;
				int-pin = < 0x1 >;
			};
			test_spi_icm42605: icm42605@13 {
				compatible = "invensense,icm42605";
				reg = < 0x13 >;
				spi-max-frequency = < 0x0 >;
				int-gpios = < &test_gpio 0x0 0x0 >;
			};
			test_spi_max6675: max6675@14 {
				compatible = "maxim,max6675";
				reg = < 0x14 >;
				spi-max-frequency = < 0x0 >;
			};
			test_spi_bmi270: bmi270@15 {
				compatible = "bosch,bmi270";
				reg = < 0x15 >;
				spi-max-frequency = < 0x0 >;
				irq-gpios = < &test_gpio 0x0 0x0 >;
			};
			test_spi_bmp388: bmp388@16 {
				compatible = "bosch,bmp388";
				reg = < 0x16 >;
				spi-max-frequency = < 0x0 >;
				int-gpios = < &test_gpio 0x0 0x0 >;
			};
			test_spi_i3g4250d: i3g4250d@17 {
				compatible = "st,i3g4250d";
				reg = < 0x17 >;
				spi-max-frequency = < 0x0 >;
			};
			test_spi_icm42670: icm42670@18 {
				compatible = "invensense,icm42670";
				reg = < 0x18 >;
				spi-max-frequency = < 0x0 >;
				int-gpios = < &test_gpio 0x0 0x0 >;
				accel-hz = < 0x320 >;
				accel-fs = < 0x10 >;
				gyro-hz = < 0x320 >;
				gyro-fs = < 0x7d0 >;
			};
			test_spi_bme680: bme680@19 {
				compatible = "bosch,bme680";
				reg = < 0x19 >;
				spi-max-frequency = < 0x0 >;
			};
			test_spi_icm426888: icm42688@1a {
				compatible = "invensense,icm42688";
				reg = < 0x1a >;
				spi-max-frequency = < 0x16e3600 >;
			};
			test_spi_max31855: max31855@1b {
				compatible = "maxim,max31855";
				reg = < 0x1b >;
				spi-max-frequency = < 0x0 >;
			};
			test_spi_max31865: max31865@1c {
				compatible = "maxim,max31865";
				reg = < 0x1c >;
				spi-max-frequency = < 0x1e848 >;
				resistance-at-zero = < 0x64 >;
				resistance-reference = < 0x1ae >;
				low-threshold = < 0x19b3 >;
				high-threshold = < 0x7fff >;
				filter-50hz;
			};
			test_spi_bmm150: bmm150@1d {
				compatible = "bosch,bmm150";
				reg = < 0x1d >;
				spi-max-frequency = < 0x0 >;
				drdy-gpios = < &test_gpio 0x0 0x0 >;
			};
			test_spi_hts221: hts221@1e {
				compatible = "st,hts221";
				reg = < 0x1e >;
				spi-max-frequency = < 0x0 >;
				drdy-gpios = < &test_gpio 0x0 0x0 >;
			};
			test_spi_adt7310: adt7310@1f {
				compatible = "adi,adt7310";
				reg = < 0x1f >;
				spi-max-frequency = < 0x0 >;
				int-gpios = < &test_gpio 0x0 0x0 >;
			};
			test_spi_bmi323: bmi323@20 {
				compatible = "bosch,bmi323";
				reg = < 0x20 >;
				spi-max-frequency = < 0x7a1200 >;
				int-gpios = < &test_gpio 0x0 0x0 >;
			};
			test_spi_lsm6dso16is: lsm6dso16is@21 {
				compatible = "st,lsm6dso16is";
				reg = < 0x21 >;
				spi-max-frequency = < 0x0 >;
				irq-gpios = < &test_gpio 0x0 0x0 >;
			};
			test_spi_lsm6dsv16x: lsm6dsv16x@22 {
				compatible = "st,lsm6dsv16x";
				reg = < 0x22 >;
				spi-max-frequency = < 0x0 >;
				int1-gpios = < &test_gpio 0x0 0x0 >;
				int2-gpios = < &test_gpio 0x0 0x0 >;
			};
			test_spi_bmi08x_accel: bmi08x@23 {
				compatible = "bosch,bmi08x-accel";
				reg = < 0x23 >;
				spi-max-frequency = < 0x0 >;
				int-gpios = < &test_gpio 0x0 0x0 >;
				int1-map-io = < 0x1 >;
				int2-map-io = < 0x0 >;
				int1-conf-io = < 0xa >;
				int2-conf-io = < 0x17 >;
				accel-hz = "800";
				accel-fs = < 0x4 >;
			};
			test_spi_bmi08x_gyro: bmi08x@24 {
				compatible = "bosch,bmi08x-gyro";
				reg = < 0x24 >;
				spi-max-frequency = < 0x0 >;
				int-gpios = < &test_gpio 0x0 0x0 >;
				int3-4-map-io = < 0x1 >;
				int3-4-conf-io = < 0x1 >;
				gyro-hz = "1000_116";
				gyro-fs = < 0x3e8 >;
			};
			test_spi_tmag5170: tmag5170@25 {
				compatible = "ti,tmag5170";
				reg = < 0x25 >;
				spi-max-frequency = < 0x0 >;
				int-gpios = < &test_gpio 0x0 0x0 >;
				operating-mode = < 0x1 >;
			};
			test_spi_adxl367: adxl367@26 {
				compatible = "adi,adxl367";
				reg = < 0x26 >;
				spi-max-frequency = < 0x0 >;
				odr = < 0x4 >;
				int1-gpios = < &test_gpio 0x0 0x0 >;
			};
			test_spi_lps22df: lps22df@27 {
				compatible = "st,lps22df";
				reg = < 0x27 >;
				spi-max-frequency = < 0x0 >;
				drdy-gpios = < &test_gpio 0x0 0x0 >;
				status = "okay";
			};
			test_spi_lis2du12: lis2du12@28 {
				compatible = "st,lis2du12";
				reg = < 0x28 >;
				spi-max-frequency = < 0x0 >;
				int1-gpios = < &test_gpio 0x0 0x0 >;
				int2-gpios = < &test_gpio 0x0 0x0 >;
				status = "okay";
			};
			test_spi_lis2de12: lis2de12@29 {
				compatible = "st,lis2de12";
				reg = < 0x29 >;
				spi-max-frequency = < 0x0 >;
				int1-gpios = < &test_gpio 0x0 0x0 >;
				int2-gpios = < &test_gpio 0x0 0x0 >;
				status = "okay";
			};
			test_spi_ens160: ens160@2a {
				compatible = "sciosense,ens160";
				reg = < 0x2a >;
				spi-max-frequency = < 0x0 >;
				int-gpios = < &test_gpio 0x0 0x0 >;
			};
			test_spi_bd8lb600fs: bd8lb600fs@2b {
				compatible = "rohm,bd8lb600fs";
				reg = < 0x2b >;
				spi-max-frequency = < 0x0 >;
				reset-gpios = < &test_gpio 0x0 0x0 >;
				instance-count = < 0x1 >;
				status = "okay";
				bd8lb600fs_diagnostics: bd8lb600fs_diagnostics {
					compatible = "rohm,bd8lb600fs-diagnostics";
					status = "okay";
					#sensor-cells = < 0x0 >;
				};
			};
			test_spi_iis328dq: iis328dq@2c {
				compatible = "st,iis328dq";
				status = "okay";
				reg = < 0x2c >;
				spi-max-frequency = < 0x0 >;
				int1-gpios = < &test_gpio 0x0 0x0 >;
				drdy-int-pad = < 0x1 >;
			};
			test_spi_lis2dux12: lis2dux12@2d {
				compatible = "st,lis2dux12";
				reg = < 0x2d >;
				spi-max-frequency = < 0x0 >;
				int1-gpios = < &test_gpio 0x0 0x0 >;
				int2-gpios = < &test_gpio 0x0 0x0 >;
				status = "okay";
			};
			test_spi_tle9104: tle9104@2e {
				compatible = "infineon,tle9104";
				reg = < 0x2e >;
				spi-max-frequency = < 0x0 >;
				status = "okay";
				tle9104_diagnostics: tle9104_diagnostics {
					compatible = "infineon,tle9104-diagnostics";
					status = "okay";
					#sensor-cells = < 0x0 >;
				};
			};
		};
		test_uart: uart@55556666 {
			compatible = "vnd,serial";
			reg = < 0x55556666 0x1000 >;
			status = "okay";
			test_uart_mhz19b: mhz19b {
				compatible = "winsen,mhz19b";
				maximum-range = < 0x2710 >;
				abc-on;
			};
			test_uart_pms7003: pms7003 {
				compatible = "plantower,pms7003";
			};
			grow_r502a {
				#address-cells = < 0x1 >;
				#size-cells = < 0x0 >;
				test_uart_grow_r502a: grow_r502a@0 {
					compatible = "hzgrow,r502a";
					reg = < 0x0 >;
					int-gpios = < &test_gpio 0x0 0x0 >;
				};
			};
			test_uart_a01nyub: a01nyub {
				compatible = "dfrobot,a01nyub";
			};
			test_uart_explorir_m: explorir-m {
				compatible = "gss,explorir-m";
			};
			test_uart_fcx_mldx5: fcx-mldx5 {
				compatible = "ap,fcx-mldx5";
			};
		};
		test_w1: w1@66660000 {
			compatible = "vnd,w1";
			reg = < 0x66660000 0x1000 >;
			#address-cells = < 0x1 >;
			#size-cells = < 0x0 >;
			status = "okay";
			test_w1_ds18b20: ds18b20 {
				compatible = "maxim,ds18b20";
				family-code = < 0x28 >;
				resolution = < 0xc >;
				status = "okay";
			};
			test_w1_ds18s20: ds18s20 {
				compatible = "maxim,ds18s20";
				family-code = < 0x10 >;
				status = "okay";
			};
		};
		test_i3c: i3c@f0cacc1a {
			#address-cells = < 0x3 >;
			#size-cells = < 0x0 >;
			compatible = "vnd,i3c";
			reg = < 0xf0cacc1a 0x1000 >;
			status = "okay";
			test_i3c_lps22hh: lps22hh@100000803E0000001 {
				compatible = "st,lps22hh";
				reg = < 0x1 0x803 0xe0000001 >;
				assigned-address = < 0x1 >;
				drdy-gpios = < &test_gpio 0x0 0x0 >;
			};
			test_i3c_lps22df: lps22df@200000803E0000002 {
				compatible = "st,lps22df";
				reg = < 0x2 0x803 0xe0000002 >;
				assigned-address = < 0x2 >;
				drdy-gpios = < &test_gpio 0x0 0x0 >;
			};
			test_i3c_lps28dfw: lps28dfw@300000803E0000003 {
				compatible = "st,lps28dfw";
				reg = < 0x3 0x803 0xe0000003 >;
				assigned-address = < 0x3 >;
				drdy-gpios = < &test_gpio 0x0 0x0 >;
			};
		};
	};
};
